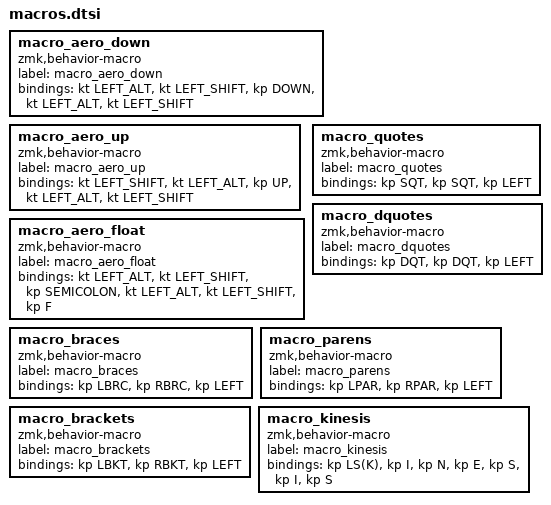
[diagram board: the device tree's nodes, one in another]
macro_aero_down: macro_aero_down{
compatible = "zmk,behavior-macro";
label = "macro_aero_down";
#binding-cells = <0>;
bindings = <&kt LEFT_ALT>, <&kt LEFT_SHIFT>, <&kp DOWN>, <&kt LEFT_ALT>, <&kt LEFT_SHIFT>;
};
macro_aero_up: macro_aero_up{
compatible = "zmk,behavior-macro";
label = "macro_aero_up";
#binding-cells = <0>;
bindings = <&kt LEFT_SHIFT>, <&kt LEFT_ALT>, <&kp UP>, <&kt LEFT_ALT>, <&kt LEFT_SHIFT>;
};
macro_aero_float: macro_aero_float{
compatible = "zmk,behavior-macro";
label = "macro_aero_float";
#binding-cells = <0>;
bindings = <&kt LEFT_ALT>, <&kt LEFT_SHIFT>, <&kp SEMICOLON>, <&kt LEFT_ALT>, <&kt LEFT_SHIFT>, <&kp F>;
};
macro_quotes: macro_quotes{
compatible = "zmk,behavior-macro";
label = "macro_quotes";
#binding-cells = <0>;
bindings = <&kp SQT>, <&kp SQT>, <&kp LEFT>;
};
macro_dquotes: macro_dquotes{
compatible = "zmk,behavior-macro";
label = "macro_dquotes";
#binding-cells = <0>;
bindings = <&kp DQT>, <&kp DQT>, <&kp LEFT>;
};
macro_braces: macro_braces{
compatible = "zmk,behavior-macro";
label = "macro_braces";
#binding-cells = <0>;
bindings = <&kp LBRC>, <&kp RBRC>, <&kp LEFT>;
};
macro_parens: macro_parens{
compatible = "zmk,behavior-macro";
label = "macro_parens";
#binding-cells = <0>;
bindings = <&kp LPAR>, <&kp RPAR>, <&kp LEFT>;
};
macro_brackets: macro_brackets{
compatible = "zmk,behavior-macro";
label = "macro_brackets";
#binding-cells = <0>;
bindings = <&kp LBKT>, <&kp RBKT>, <&kp LEFT>;
};
macro_kinesis: macro_kinesis{
compatible = "zmk,behavior-macro";
label = "macro_kinesis";
#binding-cells = <0>;
bindings = <&kp LS(K)>, <&kp I>, <&kp N>, <&kp E>, <&kp S>, <&kp I>, <&kp S>;
};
